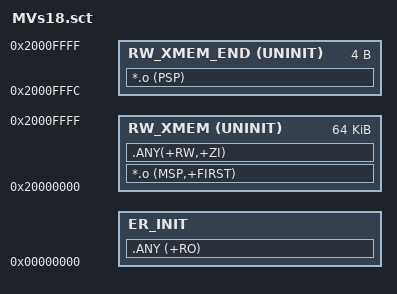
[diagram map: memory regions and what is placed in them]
; *****************************************************************************
; *** Scatter-Loading Description File generated by uVision & modify by user***
; *****************************************************************************

LR_FLASH 0x00000000 0x800000 - 255 * 1024 {;load region size_region
	ER_INIT 0x00000000  {;execution address = load address
		*.o(EXCEPT_VECTS,+First)
		startup.o
		*.o(InRoot$$Sections)
		*.o(CACHE.4KBMEM)
		*.o(.mach.init)
	}
	ER_MACH0 + 0 {*.o (.mach0.init) }
	ER_MACH1 + 0 {*.o (.mach1.init) }
	;ER_MACH2 + 0 {*.o (.mach2.init) }
	ER_MACH3 + 0 {*.o (.mach3.init) }
	ER_MACH4 + 0 {*.o (.mach4.init) }
	ER_MACH5 + 0 {*.o (.mach5.init) }
	;ER_MACH6 + 0 {*.o (.mach6.init) }
	;ER_MACH7 + 0 {*.o (.mach7.init) }
	ER_MACH8 + 0 {*.o (.mach8.init) }
	ER_MACH9 + 0 {*.o (.mach9.init) }	
	
	
	ER_NOTIFY0 + 0 {*.o (.notify0.init) }
	ER_NOTIFY1 + 0 {*.o (.notify*.init) }
	ER_NOTIFY4 + 0 {*.o (.notify4.init) }
	

	ER_SHELL0 + 0 {*.o (.shell0.cmd) }
	ER_SHELL1 + 0 {*.o (.shell1.cmd) }
	ER_SHELL2 + 0 {*.o (.shell2.cmd) }
	
	ER_ROM_ANY + 0 {
		.ANY (+RO)
	}

	;do not change the execution region name named RW_XMEM
	;you can enlarge or shrink the region size as you want
	RW_XMEM 0x20000000 UNINIT 0x10000 {;64KB XMEM
		*.o (MSP,+FIRST)
		.ANY(+RW,+ZI)
	}

	;if you want to change the RW_XMEM room,change this 0x20010000 
	;for RW_XMEM end boundary only
	RW_XMEM_END 0x20010000 - 4 UNINIT 4{
		*.o (PSP)
	}

	;you can delete the following two execute regions if you
	;want to use the whole memory totally
	;RW_VMEM 0x20010000 UNINIT 0x8000  {;32KB VMEM
 	;}

	;RW_PMEM 0x20018000 UNINIT 0x8000 {;32KB PMEM
	;}
}

